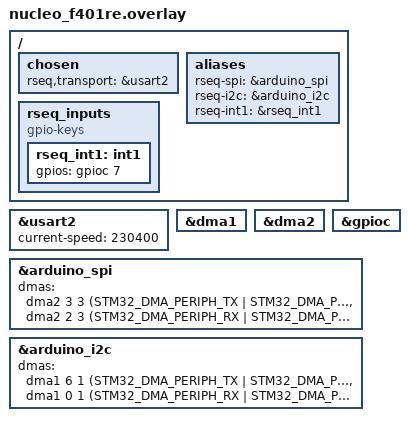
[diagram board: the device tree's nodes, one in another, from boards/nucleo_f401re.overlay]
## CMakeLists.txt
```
# SPDX-License-Identifier: Apache-2.0
#
# rseq MCU firmware (C + Rust). rust_cargo_application() builds the rustapp
# staticlib and provides main()→rust_main(); the C files are the FFI shims.

cmake_minimum_required(VERSION 3.20.0)

find_package(Zephyr REQUIRED HINTS $ENV{ZEPHYR_BASE})

project(rseq_nucleo)

rust_cargo_application()

target_sources(app PRIVATE
  src/zephyr_transport_ffi.c
  src/zephyr_bus_ffi.c
)
```

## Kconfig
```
# Copyright (c) 2026 rseq contributors
# SPDX-License-Identifier: Apache-2.0

menu "rseq MCU firmware"

choice RSEQ_TRANSPORT
	prompt "rseq-link transport"
	default RSEQ_TRANSPORT_USB_CDC
	help
	  Select the byte-stream device used by the rseq-link frame protocol.
	  Logs and shell output must not share this transport.

config RSEQ_TRANSPORT_USB_CDC
	bool "USB CDC ACM"
	help
	  Use the application CDC-ACM UART node as the rseq-link transport.

config RSEQ_TRANSPORT_UART
	bool "Hardware UART"
	help
	  Use the board-selected hardware UART as the rseq-link transport.

endchoice

endmenu

source "Kconfig.zephyr"
```

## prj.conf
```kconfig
# SPDX-License-Identifier: Apache-2.0
#
# rseq MCU firmware (Nucleo boards): rseq-link transport + physical buses.

# ---- Rust (zephyr crate supplies global allocator + panic handler + log) ----
CONFIG_RUST=y
CONFIG_RUST_ALLOC=y

# ---- Common console/log plumbing; board profiles select the backend. ----
CONFIG_CONSOLE=y
CONFIG_PRINTK=y
CONFIG_LOG=y
CONFIG_SERIAL=y
CONFIG_UART_INTERRUPT_DRIVEN=y

# ---- Optional USB CDC device stack is enabled by boards that use it. ----
CONFIG_HWINFO=y

# ---- Physical buses exposed to the rseq VM ----
CONFIG_SPI=y
CONFIG_I2C=y
CONFIG_GPIO=y

# ---- Stack: rseq-vm raw buffer + scratch + TracingBus frame during EXEC/IRQ ----
CONFIG_MAIN_STACK_SIZE=24576

# Avoid shell traffic on the rseq-link transport.
CONFIG_SHELL=n
```

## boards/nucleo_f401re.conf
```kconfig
# SPDX-License-Identifier: Apache-2.0
#
# F401RE: use ST-LINK VCP (USART2) for rseq-link. Logs must not share that
# UART, so printk/log output goes to RTT over SWD.

CONFIG_RSEQ_TRANSPORT_UART=y

CONFIG_UART_CONSOLE=n
CONFIG_LOG_BACKEND_UART=n

CONFIG_USE_SEGGER_RTT=y
CONFIG_RTT_CONSOLE=y
CONFIG_RTT_TX_RETRY_CNT=0
CONFIG_LOG_BACKEND_RTT=y
CONFIG_LOG_BACKEND_RTT_MODE_DROP=y
CONFIG_SEGGER_RTT_MODE_NO_BLOCK_SKIP=y
CONFIG_SEGGER_RTT_BUFFER_SIZE_UP=4096
CONFIG_SEGGER_RTT_PRINTF_BUFFER_SIZE=256

CONFIG_USB_DEVICE_STACK_NEXT=n
CONFIG_USBD_CDC_ACM_CLASS=n
CONFIG_CDC_ACM_SERIAL_INITIALIZE_AT_BOOT=n
CONFIG_UART_LINE_CTRL=n
```

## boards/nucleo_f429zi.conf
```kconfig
# SPDX-License-Identifier: Apache-2.0
#
# F429ZI: use the target MCU USB CDC ACM device for rseq-link and keep the
# ST-LINK VCP UART as the human-readable console/log channel.

CONFIG_RSEQ_TRANSPORT_USB_CDC=y

CONFIG_UART_CONSOLE=y
CONFIG_LOG_BACKEND_UART=y

CONFIG_USB_DEVICE_STACK_NEXT=y
CONFIG_USBD_CDC_ACM_CLASS=y
CONFIG_CDC_ACM_SERIAL_INITIALIZE_AT_BOOT=n
CONFIG_UART_LINE_CTRL=y

CONFIG_LOG_BACKEND_RTT=n
CONFIG_USE_SEGGER_RTT=n
```

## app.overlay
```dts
/*
 * Copyright (c) 2026 rseq contributors
 * SPDX-License-Identifier: Apache-2.0
 *
 * rseq MCU common overlay.
 *
 * Board-specific wiring lives in boards/<board>.overlay. Chip bus/address
 * selection is supplied by the rseq script.
 *
 * Keep transport selection in boards/<board>.overlay via /chosen
 * rseq,transport. This file is intentionally empty so boards without target
 * USB device wiring are not forced to instantiate a CDC-ACM node.
 */
```

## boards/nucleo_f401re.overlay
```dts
/*
 * Copyright (c) 2026 rseq contributors
 * SPDX-License-Identifier: Apache-2.0
 *
 * Nucleo F401RE board wiring for the rseq generic bus bridge firmware.
 */

#include <zephyr/dt-bindings/gpio/gpio.h>

#include "../app.overlay"

/ {
	chosen {
		/delete-property/ zephyr,console;
		/delete-property/ zephyr,shell-uart;
		rseq,transport = &usart2;
	};

	aliases {
		rseq-spi = &arduino_spi;
		rseq-i2c = &arduino_i2c;
		rseq-int1 = &rseq_int1;
	};

	rseq_inputs {
		compatible = "gpio-keys";

		/* Arduino D9 on Nucleo F401RE. */
		rseq_int1: int1 {
			gpios = <&gpioc 7 GPIO_ACTIVE_HIGH>;
		};
	};
};

&usart2 {
	current-speed = <230400>;
};

&dma1 {
	status = "okay";
};

&dma2 {
	status = "okay";
};

&gpioc {
	status = "okay";
};

&arduino_spi {
	dmas = <&dma2 3 3 (STM32_DMA_PERIPH_TX | STM32_DMA_PRIORITY_HIGH)
		STM32_DMA_FIFO_FULL>,
	       <&dma2 2 3 (STM32_DMA_PERIPH_RX | STM32_DMA_PRIORITY_HIGH)
		STM32_DMA_FIFO_FULL>;
	dma-names = "tx", "rx";
};

&arduino_i2c {
	dmas = <&dma1 6 1 (STM32_DMA_PERIPH_TX | STM32_DMA_PRIORITY_HIGH)
		STM32_DMA_FIFO_FULL>,
	       <&dma1 0 1 (STM32_DMA_PERIPH_RX | STM32_DMA_PRIORITY_HIGH)
		STM32_DMA_FIFO_FULL>;
	dma-names = "tx", "rx";
};
```

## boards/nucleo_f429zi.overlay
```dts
/*
 * Copyright (c) 2026 rseq contributors
 * SPDX-License-Identifier: Apache-2.0
 *
 * Nucleo F429ZI board wiring for the rseq generic bus bridge firmware.
 */

#include <zephyr/dt-bindings/gpio/gpio.h>
#include "../app.overlay"

/* USB CDC-ACM — the rseq-link transport channel. */
&zephyr_udc0 {
	cdc_acm_uart0: cdc_acm_uart0 {
		compatible = "zephyr,cdc-acm-uart";
	};
};

/ {
	chosen {
		rseq,transport = &cdc_acm_uart0;
	};

	aliases {
		rseq-spi = &arduino_spi;
		rseq-i2c = &arduino_i2c;
		rseq-int1 = &rseq_int1;
	};

	rseq_inputs {
		compatible = "gpio-keys";

		/* Arduino D9 on this board. Matches the existing tested wiring. */
		rseq_int1: int1 {
			gpios = <&gpiod 15 GPIO_ACTIVE_HIGH>;
		};
	};
};

/* Enable DMA1 for I2C; the upstream board DTS already enables DMA2. */
&dma1 {
	status = "okay";
};

&gpiod {
	status = "okay";
};

&arduino_spi {
	dmas = <&dma2 3 3 (STM32_DMA_PERIPH_TX | STM32_DMA_PRIORITY_HIGH)
		STM32_DMA_FIFO_FULL>,
	       <&dma2 2 3 (STM32_DMA_PERIPH_RX | STM32_DMA_PRIORITY_HIGH)
		STM32_DMA_FIFO_FULL>;
	dma-names = "tx", "rx";
};

&arduino_i2c {
	dmas = <&dma1 6 1 (STM32_DMA_PERIPH_TX | STM32_DMA_PRIORITY_HIGH)
		STM32_DMA_FIFO_FULL>,
	       <&dma1 0 1 (STM32_DMA_PERIPH_RX | STM32_DMA_PRIORITY_HIGH)
		STM32_DMA_FIFO_FULL>;
	dma-names = "tx", "rx";
};
```

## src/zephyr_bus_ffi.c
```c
#include <stddef.h>
#include <stdint.h>
#include <stdbool.h>
#include <errno.h>

#include <zephyr/device.h>
#include <zephyr/drivers/gpio.h>
#include <zephyr/drivers/i2c.h>
#include <zephyr/drivers/spi.h>
#include <zephyr/kernel.h>
#include <zephyr/sys/printk.h>

#define RSEQ_SPI_BUS_NODE   DT_ALIAS(rseq_spi)
#define RSEQ_I2C_BUS_NODE   DT_ALIAS(rseq_i2c)
#define RSEQ_INT1_NODE      DT_ALIAS(rseq_int1)

#define RSEQ_HAS_SPI                                                           \
    (DT_NODE_EXISTS(RSEQ_SPI_BUS_NODE) &&                                      \
     DT_NODE_HAS_PROP(RSEQ_SPI_BUS_NODE, cs_gpios))
#define RSEQ_HAS_I2C DT_NODE_EXISTS(RSEQ_I2C_BUS_NODE)
#define RSEQ_HAS_INT1 DT_NODE_EXISTS(RSEQ_INT1_NODE)

#define SPI_BUS_FREQUENCY 8000000U
#define SPI_BUS_SLAVE     0U

#define SPI_BUS_OPERATION                                                      \
    (SPI_OP_MODE_MASTER | SPI_WORD_SET(8) | SPI_TRANSFER_MSB)

#if RSEQ_HAS_SPI
static const struct device *const spi_bus = DEVICE_DT_GET(RSEQ_SPI_BUS_NODE);
static const struct spi_config    spi_cfg = {
       .frequency = SPI_BUS_FREQUENCY,
       .operation = SPI_BUS_OPERATION,
       .slave     = SPI_BUS_SLAVE,
};
static const struct gpio_dt_spec spi_cs =
    GPIO_DT_SPEC_GET_BY_IDX(RSEQ_SPI_BUS_NODE, cs_gpios, 0);
#endif

#if RSEQ_HAS_I2C
static const struct device *const i2c_bus = DEVICE_DT_GET(RSEQ_I2C_BUS_NODE);
#endif

#if RSEQ_HAS_INT1
static const struct gpio_dt_spec rseq_int1 =
    GPIO_DT_SPEC_GET(RSEQ_INT1_NODE, gpios);
static struct gpio_callback rseq_int1_cb;
K_SEM_DEFINE(rseq_int1_sem, 0, 1);
static bool rseq_int1_ready;
#endif

// 声明 Rust 侧的回调函数
extern void rust_irq_int1_triggered(void);
extern void rust_event_notify(void);

#if RSEQ_HAS_INT1
static void rseq_int1_isr(const struct device *port, struct gpio_callback *cb,
                          uint32_t pins)
{
    (void)port;
    (void)cb;
    (void)pins;
    k_sem_give(&rseq_int1_sem);
    // 同时通知 Rust 侧设置待处理标志
    rust_irq_int1_triggered();
    rust_event_notify();
}

static void rseq_int1_sem_drain(void)
{
    while (k_sem_take(&rseq_int1_sem, K_NO_WAIT) == 0) {
    }
}
#endif

int rust_spi_bus_is_ready(void)
{
#if RSEQ_HAS_SPI
    return device_is_ready(spi_bus) ? 0 : -ENODEV;
#else
    return -ENOTSUP;
#endif
}

int rust_spi_bus_transceive(const uint8_t *tx, size_t tx_len, uint8_t *rx,
                            size_t rx_len)
{
#if RSEQ_HAS_SPI
    const struct spi_buf tx_buf = {
        .buf = (void *)tx,
        .len = tx_len,
    };
    const struct spi_buf_set tx_set = {
        .buffers = &tx_buf,
        .count   = tx != NULL ? 1 : 0,
    };
    struct spi_buf rx_buf = {
        .buf = rx,
        .len = rx_len,
    };
    const struct spi_buf_set rx_set = {
        .buffers = &rx_buf,
        .count   = rx != NULL ? 1 : 0,
    };

    if (!device_is_ready(spi_bus)) {
        return -ENODEV;
    }

    return spi_transceive(spi_bus, &spi_cfg, tx != NULL ? &tx_set : NULL,
                          rx != NULL ? &rx_set : NULL);
#else
    (void)tx;
    (void)tx_len;
    (void)rx;
    (void)rx_len;
    return -ENOTSUP;
#endif
}

int rust_spi_cs_init(void)
{
#if RSEQ_HAS_SPI
    if (!gpio_is_ready_dt(&spi_cs)) {
        return -ENODEV;
    }

    return gpio_pin_configure_dt(&spi_cs, GPIO_OUTPUT_INACTIVE);
#else
    return -ENOTSUP;
#endif
}

int rust_spi_cs_set_low(void)
{
#if RSEQ_HAS_SPI
    return gpio_pin_set_raw(spi_cs.port, spi_cs.pin, 0);
#else
    return -ENOTSUP;
#endif
}

int rust_spi_cs_set_high(void)
{
#if RSEQ_HAS_SPI
    return gpio_pin_set_raw(spi_cs.port, spi_cs.pin, 1);
#else
    return -ENOTSUP;
#endif
}

int rust_i2c_bus_is_ready(void)
{
#if RSEQ_HAS_I2C
    return device_is_ready(i2c_bus) ? 0 : -ENODEV;
#else
    return -ENOTSUP;
#endif
}

int rust_i2c_bus_read(uint16_t addr, uint8_t *data, size_t len)
{
#if RSEQ_HAS_I2C
    if (!device_is_ready(i2c_bus)) {
        return -ENODEV;
    }

    return i2c_read(i2c_bus, data, len, addr);
#else
    (void)addr;
    (void)data;
    (void)len;
    return -ENOTSUP;
#endif
}

int rust_i2c_bus_write(uint16_t addr, const uint8_t *data, size_t len)
{
#if RSEQ_HAS_I2C
    if (!device_is_ready(i2c_bus)) {
        return -ENODEV;
    }

    return i2c_write(i2c_bus, data, len, addr);
#else
    (void)addr;
    (void)data;
    (void)len;
    return -ENOTSUP;
#endif
}

int rust_i2c_bus_write_read(uint16_t addr, const uint8_t *write_data,
                            size_t write_len, uint8_t *read_data,
                            size_t read_len)
{
#if RSEQ_HAS_I2C
    if (!device_is_ready(i2c_bus)) {
        return -ENODEV;
    }

    return i2c_write_read(i2c_bus, addr, write_data, write_len, read_data,
                          read_len);
#else
    (void)addr;
    (void)write_data;
    (void)write_len;
    (void)read_data;
    (void)read_len;
    return -ENOTSUP;
#endif
}

int rust_i3c_bus_is_ready(void)
{
    return -ENOTSUP;
}

int rust_i3c_bus_write_read(uint16_t addr, const uint8_t *write_data,
                            size_t write_len, uint8_t *read_data,
                            size_t read_len)
{
    (void)addr;
    (void)write_data;
    (void)write_len;
    (void)read_data;
    (void)read_len;
    return -ENOTSUP;
}

int rust_i3c_bus_write(uint16_t addr, const uint8_t *data, size_t len)
{
    (void)addr;
    (void)data;
    (void)len;
    return -ENOTSUP;
}

int rust_irq_init(void)
{
#if RSEQ_HAS_INT1
    int ret;

    if (rseq_int1_ready) {
        return 0;
    }

    if (!gpio_is_ready_dt(&rseq_int1)) {
        return -ENODEV;
    }

    ret = gpio_pin_configure_dt(&rseq_int1, GPIO_INPUT);
    if (ret != 0) {
        return ret;
    }

    gpio_init_callback(&rseq_int1_cb, rseq_int1_isr, BIT(rseq_int1.pin));
    ret = gpio_add_callback(rseq_int1.port, &rseq_int1_cb);
    if (ret != 0) {
        return ret;
    }

    ret = gpio_pin_interrupt_configure_dt(&rseq_int1, GPIO_INT_EDGE_TO_ACTIVE);
    if (ret != 0) {
        (void)gpio_remove_callback(rseq_int1.port, &rseq_int1_cb);
        return ret;
    }

    rseq_int1_sem_drain();
    rseq_int1_ready = true;
    return 0;
#else
    return -ENOTSUP;
#endif
}

int rust_irq_wait(uint8_t pin, uint32_t timeout_ms)
{
#if RSEQ_HAS_INT1
    int ret;
    int level;
    int level_after;

    if (pin != 0U) {
        return -2;
    }

    ret = rust_irq_init();
    if (ret != 0) {
        return -3;
    }

    rseq_int1_sem_drain();
    level = gpio_pin_get_dt(&rseq_int1);
    if (level < 0) {
        return -3;
    }

    printk("rseq: irq wait pin=%u timeout=%u entry_level=%d\n",
           (unsigned int)pin, (unsigned int)timeout_ms, level);
    if (level > 0) {
        printk("rseq: irq wait pin=%u already high, waiting next edge\n",
               (unsigned int)pin);
    }

    ret = k_sem_take(&rseq_int1_sem, K_MSEC(timeout_ms));
    if (ret == 0) {
        level_after = gpio_pin_get_dt(&rseq_int1);
        printk("rseq: irq edge pin=%u level=%d\n", (unsigned int)pin,
               level_after);
        return 0;
    }

    printk("rseq: irq wait timeout pin=%u\n", (unsigned int)pin);
    return -1;
#else
    (void)pin;
    (void)timeout_ms;
    return -ENOTSUP;
#endif
}

int rust_irq_level(uint8_t pin)
{
#if RSEQ_HAS_INT1
    int ret;

    if (pin != 0U) {
        return -ENOTSUP;
    }

    ret = rust_irq_init();
    if (ret != 0) {
        return ret;
    }

    return gpio_pin_get_dt(&rseq_int1);
#else
    (void)pin;
    return -ENOTSUP;
#endif
}
```

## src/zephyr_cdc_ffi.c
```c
/*
 * rseq MCU — USB CDC + UART FFI for Rust.
 *
 *  - rust_usb_enable(): bring up Zephyr's "new" USB device stack (one CDC-ACM
 *    port) so the host sees "rseq MCU CDC". Each step is printk'd for
 *    bring-up diagnostics (logs go to USART3 / ST-Link VCP).
 *  - rust_uart_init/read/write: the CDC-ACM UART (RX irq→K_MSGQ, blocking;
 *    TX uart_poll_out under a mutex) used as the rseq-link Transport.
 *  - rust_uptime_us/kernel_delay_us/sleep_ms: timing for report metadata and
 *    the Bus::delay_us path.
 *  - rust_printk: raw console output from Rust (bypasses the log backend).
 *
 * SPDX-License-Identifier: Apache-2.0
 */

#include <stddef.h>
#include <stdint.h>
#include <errno.h>

#include <zephyr/kernel.h>
#include <zephyr/device.h>
#include <zephyr/drivers/uart.h>
#include <zephyr/sys/printk.h>

#include <zephyr/usb/usbd.h>
#include <zephyr/usb/usb_ch9.h>

/* ---- USB device context + descriptors (self-contained, 1 CDC port) ---- */

#define USB_VID 0x0483
#define USB_PID 0x5740 /* ST + generic STM32 CDC; host binds cdc_acm/usbser */

USBD_DEVICE_DEFINE(udev,
		   DEVICE_DT_GET(DT_NODELABEL(zephyr_udc0)),
		   USB_VID, USB_PID);

USBD_DESC_LANG_DEFINE(udev_lang);
USBD_DESC_MANUFACTURER_DEFINE(udev_mfr, "rseq");
USBD_DESC_PRODUCT_DEFINE(udev_product, "rseq MCU CDC");
USBD_DESC_SERIAL_NUMBER_DEFINE(udev_sn); /* from hwinfo (chip UID) */
USBD_DESC_CONFIG_DEFINE(udev_cfg_desc, "CDC");

USBD_CONFIGURATION_DEFINE(udev_config,
			  USB_SCD_SELF_POWERED,
			  0, &udev_cfg_desc);

static void udev_msg_cb(struct usbd_context *const ctx, const struct usbd_msg *msg)
{
	if (usbd_can_detect_vbus(ctx)) {
		if (msg->type == USBD_MSG_VBUS_READY) {
			(void)usbd_enable(ctx);
		} else if (msg->type == USBD_MSG_VBUS_REMOVED) {
			(void)usbd_disable(ctx);
		}
	}
}

int rust_usb_enable(void)
{
	int err;

	err  = usbd_add_descriptor(&udev, &udev_lang);
	err |= usbd_add_descriptor(&udev, &udev_mfr);
	err |= usbd_add_descriptor(&udev, &udev_product);
	err |= usbd_add_descriptor(&udev, &udev_sn);
	if (err) {
		printk("rseq: usbd_add_descriptor=%d\n", err);
		return -EIO;
	}

	err = usbd_add_configuration(&udev, USBD_SPEED_FS, &udev_config);
	if (err) {
		printk("rseq: usbd_add_configuration=%d\n", err);
		return err;
	}

	/* Registers the cdc_acm_uart0 instance as a class function. */
	err = usbd_register_all_classes(&udev, USBD_SPEED_FS, 1, NULL);
	if (err) {
		printk("rseq: usbd_register_all_classes=%d\n", err);
		return err;
	}

	(void)usbd_device_set_code_triple(&udev, USBD_SPEED_FS,
					  USB_BCC_MISCELLANEOUS, 0x02, 0x01);

	err = usbd_msg_register_cb(&udev, udev_msg_cb);
	if (err) {
		printk("rseq: usbd_msg_register_cb=%d\n", err);
		return err;
	}

	err = usbd_init(&udev);
	if (err) {
		printk("rseq: usbd_init=%d\n", err);
		return err;
	}

	if (!usbd_can_detect_vbus(&udev)) {
		err = usbd_enable(&udev);
		if (err) {
			printk("rseq: usbd_enable=%d\n", err);
			return err;
		}
	}

	printk("rseq: usb ok\n");
	return 0;
}

/* ---- CDC-ACM UART (cdc_acm_uart0 from app.overlay) ---- */

#if DT_NODE_EXISTS(DT_NODELABEL(cdc_acm_uart0))
static const struct device *const serial_dev = DEVICE_DT_GET(DT_NODELABEL(cdc_acm_uart0));
#else
#error "cdc_acm_uart0 not found in devicetree (check app.overlay)"
#endif

K_MSGQ_DEFINE(uart_rx_msgq, sizeof(uint8_t), 1024, 4);
K_MUTEX_DEFINE(uart_tx_mutex);
K_SEM_DEFINE(rseq_event_sem, 0, 1);

void rust_event_notify(void)
{
	k_sem_give(&rseq_event_sem);
}

int rust_event_wait(uint32_t timeout_ms)
{
	return k_sem_take(&rseq_event_sem,
			  timeout_ms == 0U ? K_FOREVER : K_MSEC(timeout_ms));
}

static void uart_irq_cb(const struct device *dev, void *user_data)
{
	ARG_UNUSED(user_data);

	uart_irq_update(dev);
	if (!uart_irq_rx_ready(dev)) {
		return;
	}

	uint8_t buf[32];

	while (1) {
		int n = uart_fifo_read(dev, buf, sizeof(buf));
		if (n <= 0) {
			break;
		}

		for (int i = 0; i < n; i++) {
			(void)k_msgq_put(&uart_rx_msgq, &buf[i], K_NO_WAIT);
		}
		rust_event_notify();
	}
}

int rust_uart_init(void)
{
	if (!device_is_ready(serial_dev)) {
		printk("rseq: cdc_acm_uart0 not ready\n");
		return -ENODEV;
	}

	k_msgq_purge(&uart_rx_msgq);

	int ret = uart_irq_callback_user_data_set(serial_dev, uart_irq_cb, NULL);
	if (ret) {
		printk("rseq: uart_irq_callback_set=%d\n", ret);
		return ret;
	}

	uart_irq_rx_enable(serial_dev);
	return 0;
}

/* Non-blocking read: always returns immediately (0 if no data).
 * Used for IRQ polling mode. */
int rust_uart_read(uint8_t *buf, size_t len)
{
	if (len == 0 || buf == NULL) {
		return -EINVAL;
	}

	/* Non-blocking: return immediately if no data */
	int ret = k_msgq_get(&uart_rx_msgq, &buf[0], K_NO_WAIT);
	if (ret) {
		/* No data available, return 0 (not an error) */
		return 0;
	}

	size_t count = 1;
	while (count < len) {
		if (k_msgq_get(&uart_rx_msgq, &buf[count], K_NO_WAIT) != 0) {
			break;
		}
		count++;
	}

	return (int)count;
}

int rust_uart_write(const uint8_t *data, size_t len)
{
	if (len != 0 && data == NULL) {
		return -EINVAL;
	}

	if (!device_is_ready(serial_dev)) {
		return -ENODEV;
	}

#ifdef CONFIG_UART_LINE_CTRL
	uint32_t dtr = 0U;
	int ctrl_ret = uart_line_ctrl_get(serial_dev, UART_LINE_CTRL_DTR, &dtr);
	if (ctrl_ret == 0 && dtr == 0U) {
		return -ENOTCONN;
	}
#endif

	k_mutex_lock(&uart_tx_mutex, K_FOREVER);
	for (size_t i = 0; i < len; i++) {
#ifdef CONFIG_UART_LINE_CTRL
		if ((i & 0x3fU) == 0U) {
			dtr = 0U;
			ctrl_ret = uart_line_ctrl_get(serial_dev, UART_LINE_CTRL_DTR, &dtr);
			if (ctrl_ret == 0 && dtr == 0U) {
				k_mutex_unlock(&uart_tx_mutex);
				return -ENOTCONN;
			}
		}
#endif
		uart_poll_out(serial_dev, data[i]);
	}
	k_mutex_unlock(&uart_tx_mutex);
	return 0;
}

void rust_kernel_sleep_ms(uint32_t ms)
{
	k_sleep(K_MSEC(ms));
}

uint64_t rust_uptime_us(void)
{
	return k_cyc_to_us_floor64(k_cycle_get_64());
}

void rust_kernel_delay_us(uint32_t us)
{
	if (us == 0) {
		return;
	}

	uint32_t ms = us / 1000U;
	uint32_t rem = us % 1000U;

	if (ms != 0U) {
		k_sleep(K_MSEC(ms));
	}

	if (rem != 0U) {
		k_busy_wait(rem);
	}
}

/* Raw console output for Rust (bypasses the log backend; goes to USART3). */
void rust_printk(const char *s, size_t len)
{
	printk("%.*s", (int)len, s);
}
```

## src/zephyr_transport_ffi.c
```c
/*
 * rseq MCU — Zephyr transport + UART FFI for Rust.
 *
 *  - rust_transport_init/read/write: the board-selected UART-like byte stream
 *    (USB CDC-ACM or hardware UART) used as the rseq-link Transport.
 *  - CONFIG_RSEQ_TRANSPORT_USB_CDC brings up Zephyr's "new" USB device stack
 *    before binding the CDC-ACM UART.
 *  - rust_uptime_us/kernel_delay_us/sleep_ms: timing for report metadata and
 *    the Bus::delay_us path.
 *  - rust_printk: raw console output from Rust.
 *
 * SPDX-License-Identifier: Apache-2.0
 */

#include <stddef.h>
#include <stdint.h>
#include <errno.h>

#include <zephyr/kernel.h>
#include <zephyr/device.h>
#include <zephyr/drivers/uart.h>
#include <zephyr/devicetree.h>
#include <zephyr/irq.h>
#include <zephyr/sys/printk.h>

#ifdef CONFIG_RSEQ_TRANSPORT_USB_CDC
#include <zephyr/usb/usbd.h>
#include <zephyr/usb/usb_ch9.h>
#endif

/* ---- Optional USB device context + descriptors (self-contained CDC port) ---- */

#ifdef CONFIG_RSEQ_TRANSPORT_USB_CDC

#define USB_VID 0x0483
#define USB_PID 0x5740 /* ST + generic STM32 CDC; host binds cdc_acm/usbser */

USBD_DEVICE_DEFINE(udev,
		   DEVICE_DT_GET(DT_NODELABEL(zephyr_udc0)),
		   USB_VID, USB_PID);

USBD_DESC_LANG_DEFINE(udev_lang);
USBD_DESC_MANUFACTURER_DEFINE(udev_mfr, "rseq");
USBD_DESC_PRODUCT_DEFINE(udev_product, "rseq MCU CDC");
USBD_DESC_SERIAL_NUMBER_DEFINE(udev_sn); /* from hwinfo (chip UID) */
USBD_DESC_CONFIG_DEFINE(udev_cfg_desc, "CDC");

USBD_CONFIGURATION_DEFINE(udev_config,
			  USB_SCD_SELF_POWERED,
			  0, &udev_cfg_desc);

static void udev_msg_cb(struct usbd_context *const ctx, const struct usbd_msg *msg)
{
	if (usbd_can_detect_vbus(ctx)) {
		if (msg->type == USBD_MSG_VBUS_READY) {
			(void)usbd_enable(ctx);
		} else if (msg->type == USBD_MSG_VBUS_REMOVED) {
			(void)usbd_disable(ctx);
		}
	}
}

static int rust_usb_enable(void)
{
	int err;

	err  = usbd_add_descriptor(&udev, &udev_lang);
	err |= usbd_add_descriptor(&udev, &udev_mfr);
	err |= usbd_add_descriptor(&udev, &udev_product);
	err |= usbd_add_descriptor(&udev, &udev_sn);
	if (err) {
		printk("rseq: usbd_add_descriptor=%d\n", err);
		return -EIO;
	}

	err = usbd_add_configuration(&udev, USBD_SPEED_FS, &udev_config);
	if (err) {
		printk("rseq: usbd_add_configuration=%d\n", err);
		return err;
	}

	/* Registers the cdc_acm_uart0 instance as a class function. */
	err = usbd_register_all_classes(&udev, USBD_SPEED_FS, 1, NULL);
	if (err) {
		printk("rseq: usbd_register_all_classes=%d\n", err);
		return err;
	}

	(void)usbd_device_set_code_triple(&udev, USBD_SPEED_FS,
					  USB_BCC_MISCELLANEOUS, 0x02, 0x01);

	err = usbd_msg_register_cb(&udev, udev_msg_cb);
	if (err) {
		printk("rseq: usbd_msg_register_cb=%d\n", err);
		return err;
	}

	err = usbd_init(&udev);
	if (err) {
		printk("rseq: usbd_init=%d\n", err);
		return err;
	}

	if (!usbd_can_detect_vbus(&udev)) {
		err = usbd_enable(&udev);
		if (err) {
			printk("rseq: usbd_enable=%d\n", err);
			return err;
		}
	}

	printk("rseq: usb ok\n");
	return 0;
}

#endif /* CONFIG_RSEQ_TRANSPORT_USB_CDC */

/* ---- rseq transport UART-like device from /chosen rseq,transport ---- */

#if DT_HAS_CHOSEN(rseq_transport)
static const struct device *const transport_dev = DEVICE_DT_GET(DT_CHOSEN(rseq_transport));
#else
#error "missing /chosen rseq,transport in board overlay"
#endif

K_MSGQ_DEFINE(uart_rx_msgq, sizeof(uint8_t), 4096, 4);

#ifdef CONFIG_RSEQ_TRANSPORT_UART
#define UART_TX_RING_SIZE 8192U
#define UART_TX_IRQ_BUDGET 64U

static uint8_t uart_tx_ring[UART_TX_RING_SIZE];
static size_t uart_tx_head;
static size_t uart_tx_tail;
static size_t uart_tx_count;
static uint32_t uart_tx_dropped_frames;

static void uart_tx_reset(void)
{
	unsigned int key = irq_lock();

	uart_tx_head = 0U;
	uart_tx_tail = 0U;
	uart_tx_count = 0U;
	uart_tx_dropped_frames = 0U;
	irq_unlock(key);

	uart_irq_tx_disable(transport_dev);
}

static int uart_tx_enqueue(const uint8_t *data, size_t len)
{
	if (len == 0U) {
		return 0;
	}

	if (len > UART_TX_RING_SIZE) {
		return -EMSGSIZE;
	}

	unsigned int key = irq_lock();
	size_t free = UART_TX_RING_SIZE - uart_tx_count;

	if (free < len) {
		uart_tx_dropped_frames++;
		irq_unlock(key);
		return -ENOSPC;
	}

	for (size_t i = 0U; i < len; i++) {
		uart_tx_ring[uart_tx_head] = data[i];
		uart_tx_head = (uart_tx_head + 1U) % UART_TX_RING_SIZE;
	}
	uart_tx_count += len;
	irq_unlock(key);

	uart_irq_tx_enable(transport_dev);
	return 0;
}

static void uart_tx_service(const struct device *dev)
{
	for (uint32_t budget = 0U; budget < UART_TX_IRQ_BUDGET; budget++) {
		if (uart_tx_count == 0U) {
			uart_irq_tx_disable(dev);
			return;
		}

		uint8_t byte = uart_tx_ring[uart_tx_tail];
		int written = uart_fifo_fill(dev, &byte, 1);
		if (written <= 0) {
			return;
		}

		uart_tx_tail = (uart_tx_tail + 1U) % UART_TX_RING_SIZE;
		uart_tx_count--;
	}
}
#else
K_MUTEX_DEFINE(uart_tx_mutex);
#endif

K_SEM_DEFINE(rseq_event_sem, 0, 1);

void rust_event_notify(void)
{
	k_sem_give(&rseq_event_sem);
}

int rust_event_wait(uint32_t timeout_ms)
{
	return k_sem_take(&rseq_event_sem,
			  timeout_ms == 0U ? K_FOREVER : K_MSEC(timeout_ms));
}

static void uart_irq_cb(const struct device *dev, void *user_data)
{
	ARG_UNUSED(user_data);

	uart_irq_update(dev);

	if (uart_irq_rx_ready(dev)) {
		uint8_t buf[32];

		while (1) {
			int n = uart_fifo_read(dev, buf, sizeof(buf));
			if (n <= 0) {
				break;
			}

			for (int i = 0; i < n; i++) {
				(void)k_msgq_put(&uart_rx_msgq, &buf[i], K_NO_WAIT);
			}
			rust_event_notify();
		}
	}

#ifdef CONFIG_RSEQ_TRANSPORT_UART
	if (uart_irq_tx_ready(dev)) {
		uart_tx_service(dev);
	}
#endif
}

int rust_transport_init(void)
{
#ifdef CONFIG_RSEQ_TRANSPORT_USB_CDC
	int usb_ret = rust_usb_enable();
	if (usb_ret != 0) {
		return usb_ret;
	}
#endif

	if (!device_is_ready(transport_dev)) {
		printk("rseq: transport device not ready\n");
		return -ENODEV;
	}

	printk("rseq: transport=%s\n", transport_dev->name);

#ifdef CONFIG_RSEQ_TRANSPORT_UART
	struct uart_config cfg = {
		.baudrate = DT_PROP(DT_CHOSEN(rseq_transport), current_speed),
		.parity = UART_CFG_PARITY_NONE,
		.stop_bits = UART_CFG_STOP_BITS_1,
		.data_bits = UART_CFG_DATA_BITS_8,
		.flow_ctrl = UART_CFG_FLOW_CTRL_NONE,
	};

	int cfg_ret = uart_configure(transport_dev, &cfg);
	if (cfg_ret != 0 && cfg_ret != -ENOSYS) {
		printk("rseq: uart_configure=%d\n", cfg_ret);
		return cfg_ret;
	}
#endif

	k_msgq_purge(&uart_rx_msgq);

	int ret = uart_irq_callback_user_data_set(transport_dev, uart_irq_cb, NULL);
	if (ret) {
		printk("rseq: uart_irq_callback_set=%d\n", ret);
		return ret;
	}

#ifdef CONFIG_RSEQ_TRANSPORT_UART
	uart_tx_reset();
#endif

	uart_irq_rx_enable(transport_dev);
	return 0;
}

/* Non-blocking read: always returns immediately (0 if no data).
 * Used for IRQ polling mode. */
int rust_transport_read(uint8_t *buf, size_t len)
{
	if (len == 0 || buf == NULL) {
		return -EINVAL;
	}

	size_t count = 0;
	while (count < len) {
		if (k_msgq_get(&uart_rx_msgq, &buf[count], K_NO_WAIT) != 0) {
			break;
		}
		count++;
	}

#ifdef CONFIG_RSEQ_TRANSPORT_UART
	while (count < len) {
		if (uart_poll_in(transport_dev, &buf[count]) != 0) {
			break;
		}
		count++;
	}
#endif

	return (int)count;
}

int rust_transport_write(const uint8_t *data, size_t len)
{
	if (len != 0 && data == NULL) {
		return -EINVAL;
	}

	if (!device_is_ready(transport_dev)) {
		return -ENODEV;
	}

#ifdef CONFIG_RSEQ_TRANSPORT_UART
	return uart_tx_enqueue(data, len);
#else
#if defined(CONFIG_RSEQ_TRANSPORT_USB_CDC) && defined(CONFIG_UART_LINE_CTRL)
	uint32_t dtr = 0U;
	int ctrl_ret = uart_line_ctrl_get(transport_dev, UART_LINE_CTRL_DTR, &dtr);
	if (ctrl_ret == 0 && dtr == 0U) {
		return -ENOTCONN;
	}
#endif

	k_mutex_lock(&uart_tx_mutex, K_FOREVER);
	for (size_t i = 0; i < len; i++) {
#if defined(CONFIG_RSEQ_TRANSPORT_USB_CDC) && defined(CONFIG_UART_LINE_CTRL)
		if ((i & 0x3fU) == 0U) {
			dtr = 0U;
			ctrl_ret = uart_line_ctrl_get(transport_dev, UART_LINE_CTRL_DTR, &dtr);
			if (ctrl_ret == 0 && dtr == 0U) {
				k_mutex_unlock(&uart_tx_mutex);
				return -ENOTCONN;
			}
		}
#endif
		uart_poll_out(transport_dev, data[i]);
	}
	k_mutex_unlock(&uart_tx_mutex);
	return 0;
#endif
}

void rust_kernel_sleep_ms(uint32_t ms)
{
	k_sleep(K_MSEC(ms));
}

uint64_t rust_uptime_us(void)
{
	return k_cyc_to_us_floor64(k_cycle_get_64());
}

void rust_kernel_delay_us(uint32_t us)
{
	if (us == 0) {
		return;
	}

	uint32_t ms = us / 1000U;
	uint32_t rem = us % 1000U;

	if (ms != 0U) {
		k_sleep(K_MSEC(ms));
	}

	if (rem != 0U) {
		k_busy_wait(rem);
	}
}

/* Raw console output for Rust; backend is selected by the board profile. */
void rust_printk(const char *s, size_t len)
{
	printk("%.*s", (int)len, s);
}
```
